VERSION ""

NS_ :

BS_:

BU_: DBG VCU BMS MCM DCU DAQ S2C

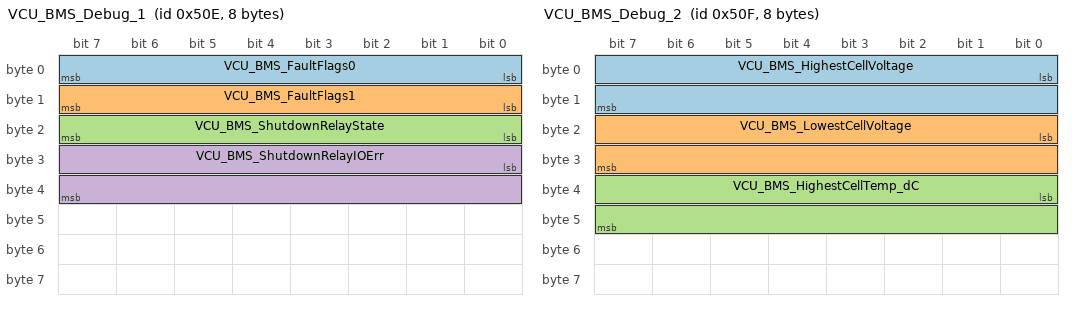
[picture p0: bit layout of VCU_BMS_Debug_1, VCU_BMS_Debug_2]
BO_ 1294 VCU_BMS_Debug_1: 8 VCU
 SG_ VCU_BMS_FaultFlags0 : 0|8@1+ (1,0) [0|255] "" VCU
 SG_ VCU_BMS_FaultFlags1 : 8|8@1+ (1,0) [0|255] "" VCU
 SG_ VCU_BMS_ShutdownRelayState : 16|8@1+ (1,0) [0|255] "" VCU
 SG_ VCU_BMS_ShutdownRelayIOErr : 24|16@1+ (1,0) [0|255] "" VCU

BO_ 1295 VCU_BMS_Debug_2: 8 VCU
 SG_ VCU_BMS_HighestCellVoltage : 0|16@1+ (1,0) [0|255] "V" VCU
 SG_ VCU_BMS_LowestCellVoltage : 16|16@1+ (1,0) [0|255] "V" VCU
 SG_ VCU_BMS_HighestCellTemp_dC : 32|16@1- (1,0) [-32768|32767] "C" VCU

CM_ BU_ VCU "The vehicle control unit";
CM_ BU_ MCM "The motor controller of the car";
CM_ BU_ BMS "The battery management system";
CM_ BU_ DCU "The dash control unit";
CM_ BO_ 160 "Motor Controller Temperatures Set 1";
CM_ BO_ 161 "Motor Controller Temperatures Set 2";
CM_ BO_ 162 "Motor Controller Temperatures Set 3";
CM_ BO_ 165 "Motor Position Information";
CM_ BO_ 166 "Motor Current Information";
CM_ BO_ 167 "Motor Voltage Information";
CM_ BO_ 192 "Motor Controller Command Messages";
CM_ BO_ 1280 "Throttle Position Sensor 0 Value";
CM_ BO_ 1281 "Throttle Position Sensor 1 Value";
CM_ BO_ 1282 "Brake Pressure Sensor Value";
CM_ BO_ 1283 "Wheel Speed Sensor Value";
CM_ BO_ 1286 "VCU Safety Messages";
CM_ BO_ 1568 "BMS Status and Fault Message";
CM_ BO_ 1571 "Accumulator Pack Voltage and Current";
CM_ BO_ 1572 "Accumulator Load Voltage and Current";
CM_ BO_ 1573 "Cell Voltage High and Low";
CM_ BO_ 1574 "Cell Voltage Average and Mismatch";
CM_ BO_ 1575 "SOC Percentage and Battery Capacity";
CM_ BO_ 1576 "Cell and BMS Board Temperature Average";
CM_ BO_ 1577 "Cell Temperature High and Low";
CM_ BO_ 1584 "BMS Board Temperature High and Low";
CM_ BO_ 1585 "Accumulator Load Power";
CM_ BO_ 1793 "Dash Control Unit Timestamp";

BA_DEF_ "BusType" STRING ;
BA_DEF_ SG_ "FieldType" STRING ;

BA_DEF_DEF_ "BusType" "CAN";
BA_DEF_DEF_ "FieldType" "";

BA_ "FieldType" SG_ 100 DRIVER_HEARTBEAT_cmd "DRIVER_HEARTBEAT_cmd";

VAL_ 100 DRIVER_HEARTBEAT_cmd 2 "DRIVER_HEARTBEAT_cmd_REBOOT" 1 "DRIVER_HEARTBEAT_cmd_SYNC" 0 "DRIVER_HEARTBEAT_cmd_NOOP" ;
